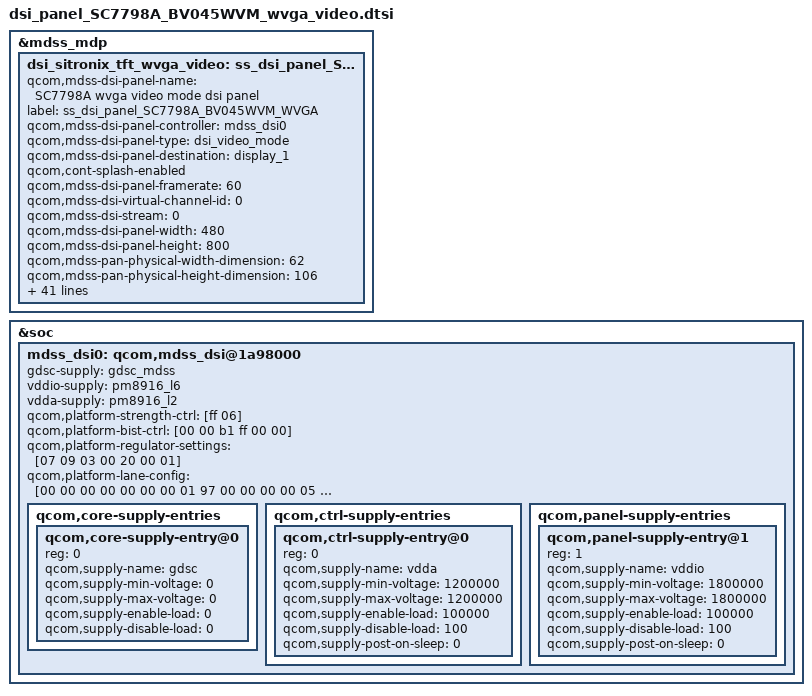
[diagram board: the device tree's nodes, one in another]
/* Copyright (c) 2013-14, Samsung Electronics Corporation. All rights reserved.
 *
 * This program is free software; you can redistribute it and/or modify
 * it under the terms of the GNU General Public License version 2 and
 * only version 2 as published by the Free Software Foundation.
 *
 * This program is distributed in the hope that it will be useful,
 * but WITHOUT ANY WARRANTY; without even the implied warranty of
 * MERCHANTABILITY or FITNESS FOR A PARTICULAR PURPOSE.  See the
 * GNU General Public License for more details.
 */

/*---------------------------------------------------------------------------
 * This file is autogenerated file using gcdb parser. Please do not edit it.
 * Update input XML file to add a new entry or update variable in this file
 * VERSION = "1.0"
 *---------------------------------------------------------------------------*/
&mdss_mdp {
	dsi_sitronix_tft_wvga_video: ss_dsi_panel_SC7798A_BV045WVM_WVGA/*qcom,mdss_dsi_sitronix_wvga_video*/ {
		qcom,mdss-dsi-panel-name = "SC7798A wvga video mode dsi panel";
		label = "ss_dsi_panel_SC7798A_BV045WVM_WVGA";
		qcom,mdss-dsi-panel-controller = <&mdss_dsi0>;
		qcom,mdss-dsi-panel-type = "dsi_video_mode";
		qcom,mdss-dsi-panel-destination = "display_1";
		qcom,cont-splash-enabled;
		qcom,mdss-dsi-panel-framerate = <60>;
		qcom,mdss-dsi-virtual-channel-id = <0>;
		qcom,mdss-dsi-stream = <0>;
		qcom,mdss-dsi-panel-width = <480>;
		qcom,mdss-dsi-panel-height = <800>;
		qcom,mdss-pan-physical-width-dimension = <62>; /* <Width> real size of panel in mm */
		qcom,mdss-pan-physical-height-dimension = <106>; /*<Height> real size of panel in mm */
		qcom,mdss-dsi-lp11-init;
		qcom,mdss-dsi-init-delay-us = <100>;
		qcom,mdss-dsi-h-front-porch = <140>;
		qcom,mdss-dsi-h-back-porch = <132>;
		qcom,mdss-dsi-h-pulse-width = <4>;
		qcom,mdss-dsi-h-sync-skew = <0>;
		qcom,mdss-dsi-v-back-porch = <12>;
		qcom,mdss-dsi-v-front-porch = <10>;
		qcom,mdss-dsi-v-pulse-width = <4>;
		qcom,mdss-dsi-h-left-border = <0>;
		qcom,mdss-dsi-h-right-border = <0>;
		qcom,mdss-dsi-v-top-border = <0>;
		qcom,mdss-dsi-v-bottom-border = <0>;
		qcom,mdss-dsi-bpp = <24>;
		qcom,mdss-dsi-color-order = <0>;
		qcom,mdss-dsi-underflow-color = <0xff>;
		qcom,mdss-dsi-border-color = <0>;
		qcom,mdss-dsi-dma-trigger = "trigger_sw";
		qcom,mdss-dsi-mdp-trigger = "none";
		qcom,mdss-dsi-bl-min-level = <1>;
		qcom,mdss-dsi-bl-max-level = <255>;
		qcom,mdss-dsi-bl-pmic-control-type = "bl_ctrl_dcs";
		qcom,mdss-dsi-lane-0-state;
		qcom,mdss-dsi-lane-1-state;
		qcom,mdss-dsi-bllp-eof-power-mode;
		qcom,mdss-dsi-bllp-power-mode;
		qcom,mdss-dsi-traffic-mode = "burst_mode";
		qcom,mdss-force-clk-lane-hs = <0>;
		qcom,mdss-dsi-reset-sequence = <1 20>, <0 1>, <1 150>;
		qcom,mdss-dsi-h-sync-pulse = <0>;
		qcom,mdss-dsi-panel-timings = [87 1C 12 00 40 44 16 1E 17 03 04 00];
		qcom,mdss-dsi-t-clk-pre = <0x27>;
		qcom,mdss-dsi-t-clk-post = <0x04>;
		qcom,mdss-dsi-on-command = [
					/* < Power Setting Sequence(1) > */
					39 01 00 00 00 00 04 B9 F1 08 00 //EXTC
					39 01 00 00 00 00 08 B1 31 0C 0C A7 33 01 B7 //POWER
					39 01 00 00 00 00 04 C6 00 00 FD //SOURCE EQ
					39 01 00 00 00 00 05 E3 03 03 03 03 //SOURCE EQ
					39 01 00 00 0A 00 03 B8 06 22 //EXT POWER
					/* < Initializing Sequence(2) > */
					39 01 00 00 00 00 13 BA 31 00 44 25 91 0A 00 00 C2 34 00 00 04 02 1D B9 EE 40 //MIPI CHARACTERISTIC
					39 01 00 00 00 00 09 B3 00 00 00 00 0C 0A 25 20 //RGB INTERFACE
					39 01 00 00 00 00 02 B4 00 //COLVMN INVERTION
					39 01 00 00 00 00 02 CC 0E //DGC
					39 01 00 00 00 00 02 BC 67 //VDC
					39 01 00 00 00 00 02 B2 03 //PANEL RSO
					39 01 00 00 00 00 06 C0 73 50 00 08 70 //SCR
					39 01 00 00 00 00 34 E9 00 00 06 00 00 6E 29 12 30 00 48 08 6E 29 47 03 //GIP1 TIMMING
						00 00 00 00 00 18 00 00 89 98 33 11 77 55 13 00 00 89 98 22 00 66 44 02
						00 00 00 00 00 00 00 00 00 00 00
					39 01 00 00 00 00 25 EA 00 00 98 98 44 66 00 22 20 00 00 98 98 55 77 11 //GIP2 TIMMING
						33 31 30 00 00 FF 01 00 00 00 00 00 00 00 00 00 00 00 00 00
					/* < Gamma Setting Sequence(3) > */
					39 01 00 00 00 00 23 E0 01 09 0D 2E 36 3F 10 31 07 0D 11 15 13 16 15 32 //GAMMA
						38 01 05 05 30 35 3F 0E 30 04 09 0A 0D 12 0D 0F 2C 35
					/* < Display on Sequence> */
					39 01 00 00 00 00 02 C7 C0
					39 01 00 00 00 00 03 C8 11 01
					39 01 00 00 00 00 02 53 24
					05 01 00 00 78 00 02 11 00
					05 01 00 00 0A 00 02 29 00
					];
		qcom,mdss-dsi-on-command-state = "dsi_lp_mode";
		qcom,mdss-dsi-off-command-state = "dsi_hs_mode";
		qcom,mdss-dsi-off-command = [39 01 00 00 46 00 02 28 00
					39 01 00 00 46 00 02 10 00];
	};
};
&soc {
	mdss_dsi0: qcom,mdss_dsi@1a98000 {
		gdsc-supply = <&gdsc_mdss>;
		vddio-supply = <&pm8916_l6>;
		vdda-supply = <&pm8916_l2>;
		qcom,platform-strength-ctrl = [ff 06];
		qcom,platform-bist-ctrl = [00 00 b1 ff 00 00];
		qcom,platform-regulator-settings = [07 09 03 00 20 00 01];
		qcom,platform-lane-config = [00 00 00 00 00 00 00 01 97
			00 00 00 00 05 00 00 01 97
			00 00 00 00 0a 00 00 01 97
			00 00 00 00 0f 00 00 01 97
			00 c0 00 00 00 00 00 01 bb];
		qcom,core-supply-entries {
			#address-cells = <1>;
			#size-cells = <0>;

			qcom,core-supply-entry@0 {
				reg = <0>;
				qcom,supply-name = "gdsc";
				qcom,supply-min-voltage = <0>;
				qcom,supply-max-voltage = <0>;
				qcom,supply-enable-load = <0>;
				qcom,supply-disable-load = <0>;
			};
		};
		qcom,ctrl-supply-entries {
			#address-cells = <1>;
			#size-cells = <0>;

			qcom,ctrl-supply-entry@0 {
				reg = <0>;
				qcom,supply-name = "vdda";
				qcom,supply-min-voltage = <1200000>;
				qcom,supply-max-voltage = <1200000>;
				qcom,supply-enable-load = <100000>;
				qcom,supply-disable-load = <100>;
				qcom,supply-post-on-sleep = <0>;
			};
		};
		qcom,panel-supply-entries {
			#address-cells = <1>;
			#size-cells = <0>;

			qcom,panel-supply-entry@1 {
				reg = <1>;
				qcom,supply-name = "vddio";
				qcom,supply-min-voltage = <1800000>;
				qcom,supply-max-voltage = <1800000>;
				qcom,supply-enable-load = <100000>;
				qcom,supply-disable-load = <100>;
				qcom,supply-post-on-sleep = <0>;
			};
		};
	};
};

